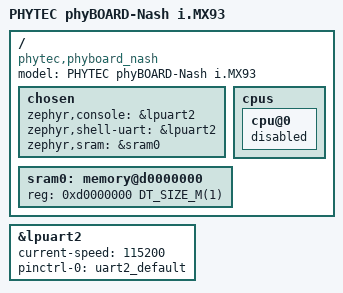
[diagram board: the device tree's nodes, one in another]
/*
 * Copyright 2022,2024 NXP
 * Copyright 2024 PHYTEC Messtechnik GmbH
 *
 * SPDX-License-Identifier: Apache-2.0
 */

/dts-v1/;

#include <nxp/nxp_mimx93_a55.dtsi>
#include "phyboard_nash-pinctrl.dtsi"

/ {
	compatible = "phytec,phyboard_nash";
	model = "PHYTEC phyBOARD-Nash i.MX93";

	chosen {
		zephyr,console = &lpuart2;
		zephyr,shell-uart = &lpuart2;
		zephyr,sram = &sram0;
	};

	cpus {
		cpu@0 {
			status = "disabled";
		};
	};

	sram0: memory@d0000000 {
		reg = <0xd0000000 DT_SIZE_M(1)>;
	};
};

&lpuart2 {
	current-speed = <115200>;
	/* clocks = <&ccm IMX_CCM_UART4_CLK 0x6c 24>; */
	pinctrl-0 = <&uart2_default>;
	pinctrl-names = "default";
	status = "okay";
};
